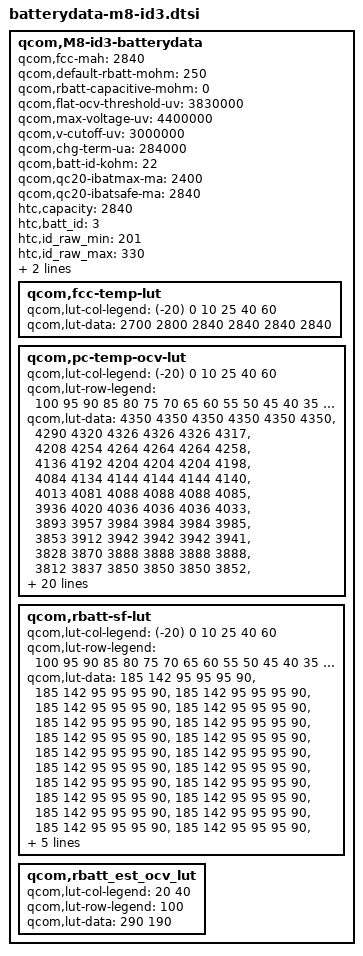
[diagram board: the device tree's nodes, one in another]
qcom,M8-id3-batterydata {
	qcom,fcc-mah = <2840>;
	qcom,default-rbatt-mohm = <250>;
	qcom,rbatt-capacitive-mohm = <0>;
	qcom,flat-ocv-threshold-uv = <3830000>;
	qcom,max-voltage-uv = <4400000>;
	qcom,v-cutoff-uv = <3000000>;
	qcom,chg-term-ua = <284000>;
	qcom,batt-id-kohm = <22>;
	qcom,qc20-ibatmax-ma = <2400>;
	qcom,qc20-ibatsafe-ma = <2840>;
	htc,capacity = <2840>;
	htc,batt_id = <3>;
	htc,id_raw_min = <201>;
	htc,id_raw_max = <330>;
	htc,type = <1>;
	htc,model_name = "B0P6B100";

	qcom,fcc-temp-lut {
		qcom,lut-col-legend = <(-20) 0 10 25 40 60>;
		qcom,lut-data = <2700 2800 2840 2840 2840 2840>;
	};

	qcom,pc-temp-ocv-lut {
		qcom,lut-col-legend = <(-20) 0 10 25 40 60>;
		qcom,lut-row-legend = <100 95 90 85 80 75 70 65 60 55 50 45 40 35 30 25 20 16 13 11 10 9 8 7 6 5 4 3 2 1 0>;
		qcom,lut-data = <4350 4350 4350 4350 4350 4350>,
				<4290 4320 4326 4326 4326 4317>,
				<4208 4254 4264 4264 4264 4258>,
				<4136 4192 4204 4204 4204 4198>,
				<4084 4134 4144 4144 4144 4140>,
				<4013 4081 4088 4088 4088 4085>,
				<3936 4020 4036 4036 4036 4033>,
				<3893 3957 3984 3984 3984 3985>,
				<3853 3912 3942 3942 3942 3941>,
				<3828 3870 3888 3888 3888 3888>,
				<3812 3837 3850 3850 3850 3852>,
				<3800 3811 3824 3824 3824 3826>,
				<3787 3792 3804 3804 3804 3804>,
				<3772 3782 3786 3786 3786 3785>,
				<3758 3773 3771 3771 3771 3767>,
				<3742 3761 3758 3758 3758 3736>,
				<3724 3742 3738 3738 3738 3716>,
				<3708 3720 3717 3717 3717 3695>,
				<3693 3700 3696 3696 3696 3676>,
				<3682 3686 3684 3684 3684 3667>,
				<3676 3682 3682 3682 3682 3666>,
				<3667 3678 3679 3679 3679 3664>,
				<3658 3672 3676 3676 3676 3662>,
				<3646 3668 3673 3673 3673 3658>,
				<3631 3661 3666 3666 3666 3648>,
				<3611 3646 3646 3646 3646 3620>,
				<3578 3612 3604 3604 3604 3572>,
				<3526 3556 3546 3546 3546 3512>,
				<3448 3479 3466 3466 3466 3429>,
                                                <3326 3363 3347 3347 3347 3298>,
                                                <3000 3000 3000 3000 3000 3000>;
	};

	qcom,rbatt-sf-lut {
		qcom,lut-col-legend = <(-20) 0 10 25 40 60>;
		qcom,lut-row-legend = <100 95 90 85 80 75 70 65 60 55 50 45 40 35 30 25 20 16 13 11 10 9 8 7 6 5 4 3 2 1>;
		qcom,lut-data = <185 142 95 95 95 90>,
				<185 142 95 95 95 90>,
				<185 142 95 95 95 90>,
				<185 142 95 95 95 90>,
				<185 142 95 95 95 90>,
				<185 142 95 95 95 90>,
				<185 142 95 95 95 90>,
				<185 142 95 95 95 90>,
				<185 142 95 95 95 90>,
				<185 142 95 95 95 90>,
				<185 142 95 95 95 90>,
				<185 142 95 95 95 90>,
				<185 142 95 95 95 90>,
				<185 142 95 95 95 90>,
				<185 142 95 95 95 90>,
				<185 142 95 95 95 90>,
				<185 142 95 95 95 90>,
				<185 142 95 95 95 90>,
				<185 142 95 95 95 90>,
				<185 142 95 95 95 90>,
				<185 142 95 95 95 90>,
				<185 142 95 95 95 90>,
				<185 142 95 95 95 90>,
				<185 142 95 95 95 90>,
				<185 142 95 95 95 90>,
				<185 142 95 95 95 90>,
                                                <185 142 95 95 95 90>,
	                                    <185 142 95 95 95 90>,
				<185 142 95 95 95 90>,
				<185 142 95 95 95 90>;
		};

	qcom,rbatt_est_ocv_lut {
		qcom,lut-col-legend = <20 40>;
		qcom,lut-row-legend = <100>;
		qcom,lut-data = <290 190>;
		};
	};

